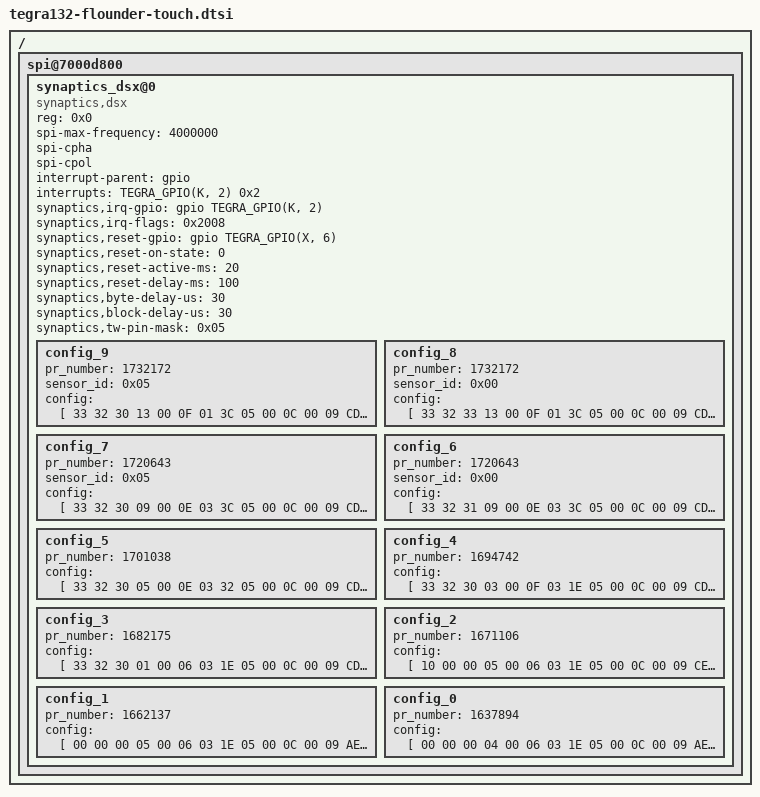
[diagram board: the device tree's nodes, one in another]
/ {
	spi@7000d800 {
		synaptics_dsx@0 {
			compatible = "synaptics,dsx";
			reg = <0x0>;
			spi-max-frequency = <4000000>;
			spi-cpha;
			spi-cpol;
			interrupt-parent = <&gpio>;
			interrupts = <TEGRA_GPIO(K, 2) 0x2>;
			synaptics,irq-gpio = <&gpio TEGRA_GPIO(K, 2) 0x00>;
			synaptics,irq-flags = <0x2008>;
			synaptics,reset-gpio = <&gpio TEGRA_GPIO(X, 6) 0x00>;
			synaptics,reset-on-state = <0>;
			synaptics,reset-active-ms = <20>;
			synaptics,reset-delay-ms = <100>;
			synaptics,byte-delay-us = <30>;
			synaptics,block-delay-us = <30>;
			synaptics,tw-pin-mask = <0x05>;

			config_9 {
				pr_number     = <1732172>;
				sensor_id     = <0x05>;
				config = [
					33 32 30 13 00 0F 01 3C
					05 00 0C 00 09 CD 4C CD
					4C 0D 0D 00 00 26 1C 1E
					05 92 14 58 07 32 36 FF
					38 FE F0 D2 F0 D2 C3 80
					C4 C4 05 03 1C 23 00 0F
					0A 20 01 01 05 00 00 0A
					C0 19 32 26 26 80 80 00
					00 C8 2F 14 00 10 B4 00
					14 00 00 00 00 00 00 FC
					E6 00 00 0A 32 50 99 40
					00 50 00 00 55 00 80 00
					01 64 00 FF FF 5A 5A 01
					40 40 32 04 00 00 00 00
					00 0C 00 09 50 64 00 00
					00 00 4C 04 6C 07 1E 05
					00 00 00 01 05 0A 00 01
					14 03 06 0F 0A FF 00 C8
					00 80 04 1B 00 00 00 E8
					03 FF FF BF F5 FF FF 00
					C0 80 00 71 00 E8 03 01
					00 03 03 07 07 00 E8 03
					02 04 01 04 83 2C 00 14
					00 00 00 02 00 02 56 03
					2B 00 13 00 01 00 02 00
					02 5A 03 2A 00 13 00 02
					00 02 00 02 5C 03 29 00
					12 00 03 00 02 00 02 5E
					83 28 00 12 00 02 02 02
					00 02 60 83 28 00 12 00
					05 00 02 00 02 62 83 27
					00 11 00 02 04 02 00 02
					64 82 25 00 11 00 06 02
					02 00 02 68 05 05 05 05
					05 05 05 04 04 04 04 04
					04 04 04 04 04 04 04 04
					04 04 04 04 04 04 04 04
					04 04 04 04 05 05 05 05
					05 05 0B 0B 0B 0B 0B 0B
					0B 0B 0B 07 07 07 07 07
					07 07 07 07 07 07 07 07
					07 07 07 07 07 07 07 07
					07 07 07 07 07 07 07 07
					0F 0F 07 07 07 07 07 05
					05 05 03 03 03 02 02 02
					01 01 01 01 01 01 01 01
					01 03 05 0F 1B 1B 01 00
					07 1B 1B 05 01 07 1E 00
					05 00 A6 00 14 64 01 00
					00 03 03 00 00 07 07 00
					32 05 06 00 35 35 00 05
					00 00 07 07 06 06 00 00
					03 05 32 C8 0C 26 0A 01
					05 08 08 A0 00 A0 00 64
					64 80 FE 00 00 00 00 00
					00 63 00 05 00 00 00 00
					0B 00 00 00 00 00 B2 03
					14 00 06 AB 03 14 00 06
					00 15 5B 50 5A 32 1E 00
					12 00 90 C6 00 3E 41 47
					49 37 3F 35 33 30 36 24
					4A 1F 1E 22 1A 1B 16 18
					34 32 31 2F 2B 28 2C 2A
					25 2D 23 20 21 1D 1C 17
					19 14 13 0F 0A 10 0C 0B
					05 03 08 06 0E 09 07 52
					56 5C 5E 54 55 53 58 57
					59 5B 5D 60 5F 63 62 02
					10 02 10 02 10 02 10 00
					10 00 10 00 10 00 10 F0
					0A 0A 0A 0A 1E
				];
			};

			config_8 {
				pr_number     = <1732172>;
				sensor_id     = <0x00>;
				config = [
					33 32 33 13 00 0F 01 3C
					05 00 0C 00 09 CD 4C CD
					4C 0D 0D 00 00 26 1C 1E
					05 86 16 CD 07 32 33 FF
					2E 00 F0 D2 F0 D2 C3 80
					C4 C4 05 03 1C 23 00 0F
					0A 20 01 01 05 00 00 0A
					C0 19 32 26 26 80 80 00
					00 C8 2F 14 00 10 B4 00
					14 00 00 00 00 00 00 FC
					E6 00 00 0A 32 50 99 40
					00 50 00 00 55 00 80 00
					01 64 00 FF FF 5A 5A 01
					40 40 32 04 00 00 00 00
					00 0C 00 09 50 64 00 00
					00 00 4C 04 6C 07 1E 05
					00 00 00 01 05 0A 00 01
					14 03 06 0F 0A FF 04 C8
					00 80 04 1B 00 00 00 E8
					03 FF FF BF F5 FF FF 00
					C0 80 00 71 00 E8 03 01
					00 03 03 07 07 00 E8 03
					02 04 01 04 85 3F 00 14
					00 00 00 02 00 02 56 04
					3D 00 13 00 01 00 02 00
					02 5A 04 3C 00 13 00 02
					00 02 00 02 5C 04 3B 00
					12 00 03 00 02 00 02 5E
					84 39 00 12 00 03 01 02
					00 02 60 84 38 00 12 00
					05 00 02 00 02 62 84 37
					00 11 00 03 03 02 00 02
					64 84 35 00 11 00 02 06
					02 00 02 68 05 05 05 05
					05 05 05 04 04 04 04 04
					04 04 04 04 04 04 04 04
					04 04 04 04 04 04 04 04
					04 04 04 04 05 05 05 05
					05 05 0B 0B 0B 0B 0B 0B
					0B 0B 0B 07 07 07 07 07
					07 07 07 07 07 07 07 07
					07 07 07 07 07 07 07 07
					07 07 07 07 07 07 07 07
					0F 0F 0F 0B 0C 09 07 05
					05 05 03 03 03 01 00 00
					00 00 01 00 01 01 02 02
					04 03 05 0F 1B 1B 01 00
					07 1B 1B 05 01 07 1E 00
					05 00 A6 00 14 64 03 00
					00 03 03 00 00 07 07 00
					2F 05 06 00 35 35 00 05
					00 00 07 07 06 06 00 00
					03 05 32 C8 0C 26 0A 01
					00 05 05 A0 00 A0 00 64
					64 80 FE 00 00 00 00 00
					00 63 00 05 00 00 00 00
					0B 00 00 00 00 00 B2 03
					14 00 06 9B 03 14 00 06
					00 15 5A 50 5A 32 1E 00
					79 00 10 C0 00 3E 41 47
					49 37 3F 35 33 30 36 24
					4A 1F 1E 22 1A 1B 16 18
					34 32 31 2F 2B 28 2C 2A
					25 2D 23 20 21 1D 1C 17
					19 14 13 0F 0A 10 0C 0B
					05 03 08 06 0E 09 07 52
					56 5C 5E 54 55 53 58 57
					59 5B 5D 60 5F 63 62 02
					10 02 10 02 10 02 10 00
					10 00 10 00 10 00 10 F0
					0A 0A 0A 0A 1E
				];
			};

			config_7 {
				pr_number     = <1720643>;
				sensor_id     = <0x05>;
				config = [
					33 32 30 09 00 0E 03 3C
					05 00 0C 00 09 CD 4C CD
					4C 0D 0D 00 00 26 1C 1E
					05 92 14 58 07 32 36 FF
					38 FE F0 D2 F0 D2 C3 80
					C4 C4 05 03 1C 23 00 0F
					0A 20 01 01 05 00 00 0A
					C0 19 32 26 26 80 80 00
					00 C8 2F 14 00 10 B4 00
					14 00 00 00 00 00 00 FC
					E6 00 00 0A 32 50 99 40
					00 50 00 00 55 00 80 00
					01 64 00 FF FF 5A 5A 01
					40 40 32 04 00 00 00 00
					00 0C 00 09 50 64 00 00
					00 00 4C 04 6C 07 1E 05
					00 00 00 01 05 0A 00 01
					14 03 06 0F 0A FF 04 C8
					00 80 04 1B 00 00 00 E8
					03 FF FF BF F5 FF FF 00
					C0 80 00 71 00 E8 03 01
					00 03 03 07 07 00 E8 03
					02 05 01 04 83 28 00 14
					00 00 00 02 00 02 56 03
					28 00 13 00 01 00 02 00
					02 5A 03 28 00 13 00 02
					00 02 00 02 5C 03 28 00
					12 00 03 00 02 00 02 5E
					83 28 00 12 00 04 00 02
					00 02 60 03 28 00 12 00
					05 00 02 00 02 62 83 28
					00 11 00 06 00 02 00 02
					64 83 28 00 11 00 07 00
					02 00 02 66 05 05 05 05
					05 05 05 04 04 04 04 04
					04 04 04 04 04 04 04 04
					04 04 04 04 04 04 04 04
					04 04 04 04 05 05 05 05
					05 05 0B 0B 0B 0B 0B 0B
					0B 0B 0B 07 07 07 07 07
					07 07 07 07 07 07 07 07
					07 07 07 07 07 07 07 07
					07 07 07 07 07 07 07 07
					0F 0F 07 07 07 07 07 05
					05 05 03 03 03 02 02 02
					01 01 01 01 01 01 01 01
					01 03 05 0F 1B 1B 01 00
					07 1B 1B 05 01 07 1E 00
					05 00 A6 00 14 64 01 00
					00 03 03 00 00 07 07 00
					32 05 06 00 35 35 00 05
					00 00 07 07 06 06 00 00
					03 05 32 C8 0C 26 0A 01
					05 08 08 A0 00 A0 00 64
					64 80 FE 00 00 00 00 00
					00 63 00 05 00 00 00 00
					0B 00 00 00 00 00 B2 03
					14 00 06 AB 03 14 00 06
					00 15 5B 50 5A 32 1E 00
					0A 00 90 C0 00 3E 41 47
					49 37 3F 35 33 30 36 24
					4A 1F 1E 22 1A 1B 16 18
					34 32 31 2F 2B 28 2C 2A
					25 2D 23 20 21 1D 1C 17
					19 14 13 0F 0A 10 0C 0B
					05 03 08 06 0E 09 07 52
					56 5C 5E 54 55 53 58 57
					59 5B 5D 60 5F 63 62 02
					10 02 10 02 10 02 10 00
					10 00 10 00 10 00 10 F0
					0A 0A 0A 0A 1E
				];
			};

			config_6 {
				pr_number     = <1720643>;
				sensor_id     = <0x00>;
				config = [
					33 32 31 09 00 0E 03 3C
					05 00 0C 00 09 CD 4C CD
					4C 0D 0D 00 00 26 1C 1E
					05 86 16 CD 07 32 33 FF
					2E 00 F0 D2 F0 D2 C3 80
					C4 C4 05 03 1C 23 00 0F
					0A 20 01 01 05 00 00 0A
					C0 19 32 26 26 80 80 00
					00 C8 2F 14 00 10 B4 00
					14 00 01 00 00 00 00 FC
					E6 00 00 0A 32 50 99 40
					00 50 00 00 55 00 80 00
					01 64 00 FF FF 5A 5A 01
					40 40 32 04 00 00 00 00
					00 0C 00 09 50 64 00 00
					00 00 4C 04 6C 07 1E 05
					00 00 00 01 05 0A 00 01
					14 03 06 0F 0A FF 04 C8
					00 80 04 1B 00 00 00 E8
					03 FF FF BF F5 FF FF 00
					C0 80 00 71 00 E8 03 01
					00 03 03 07 07 00 E8 03
					02 05 01 04 83 29 00 14
					00 00 00 02 00 02 56 03
					28 00 13 00 01 00 02 00
					02 5A 03 27 00 13 00 01
					01 02 00 02 5C 02 26 00
					12 00 02 01 02 00 02 5E
					82 25 00 12 00 03 01 02
					00 02 60 82 24 00 12 00
					03 02 02 00 02 62 82 23
					00 11 00 04 02 02 00 02
					64 82 22 00 11 00 05 03
					02 00 02 68 05 05 05 05
					05 05 05 04 04 04 04 04
					04 04 04 04 04 04 04 04
					04 04 04 04 04 04 04 04
					04 04 04 04 05 05 05 05
					05 05 0B 0B 0B 0B 0B 0B
					0B 0B 0B 07 07 07 07 07
					07 07 07 07 07 07 07 07
					07 07 07 07 07 07 07 07
					07 07 07 07 07 07 07 07
					0F 0F 08 08 08 07 07 05
					05 05 03 03 03 01 02 02
					00 00 01 01 01 01 01 01
					01 03 05 0F 1B 1B 01 00
					07 1B 1B 05 01 07 1E 00
					05 00 A6 00 14 64 01 00
					00 03 03 00 00 07 07 00
					32 05 06 00 35 35 00 05
					00 00 07 07 06 06 00 00
					03 05 32 C8 0C 26 0A 01
					05 08 08 A0 00 A0 00 64
					64 80 FE 00 00 00 00 00
					00 63 00 05 00 00 00 00
					0B 00 00 00 00 00 B2 03
					14 00 06 9B 03 14 00 06
					00 15 5B 50 5A 32 1E 00
					0A 00 90 C0 00 3E 41 47
					49 37 3F 35 33 30 36 24
					4A 1F 1E 22 1A 1B 16 18
					34 32 31 2F 2B 28 2C 2A
					25 2D 23 20 21 1D 1C 17
					19 14 13 0F 0A 10 0C 0B
					05 03 08 06 0E 09 07 52
					56 5C 5E 54 55 53 58 57
					59 5B 5D 60 5F 63 62 02
					10 02 10 02 10 02 10 00
					10 00 10 00 10 00 10 F0
					0A 0A 0A 0A 1E
				];
			};

			config_5 {				/* JDI */
				pr_number     = <1701038>;
				config = [
					33 32 30 05 00 0E 03 32
					05 00 0C 00 09 CD 4C CD
					4C 0D 0D 00 00 26 1C 1E
					05 AA 15 1E 05 2D 30 FD
					43 FA F0 D2 F0 D2 C3 80
					C4 C4 05 03 1E 28 00 0F
					0A 20 01 01 05 00 00 0A
					C0 19 32 26 26 80 80 00
					00 C8 2F 14 00 10 B4 00
					14 00 01 00 00 00 00 FC
					E6 00 00 0A 32 50 99 40
					00 50 00 00 55 00 80 00
					01 64 00 FF FF 80 80 01
					40 40 32 04 00 00 00 00
					00 0C 00 09 50 64 00 00
					00 00 4C 04 6C 07 1E 05
					00 00 00 01 05 0A 00 01
					14 03 06 0F 0A FF 00 C8
					00 80 04 1B 00 00 00 E8
					03 FF FF BF 32 FF FF 00
					C0 80 00 71 00 E8 03 01
					00 03 03 07 07 00 E8 03
					02 05 01 04 83 30 00 14
					00 00 00 02 00 02 56 03
					2F 00 13 00 01 00 02 00
					02 5A 83 2E 00 13 00 02
					00 02 00 02 5C 03 2D 00
					12 00 03 00 02 00 02 5E
					03 2C 00 12 00 04 00 02
					00 02 60 03 2B 00 12 00
					05 00 02 00 02 62 83 2A
					00 11 00 06 00 02 00 02
					64 83 28 00 11 00 08 00
					02 00 02 68 05 05 05 05
					05 05 05 04 04 04 04 04
					04 04 04 04 04 04 04 04
					04 04 04 04 04 04 04 04
					04 04 04 04 05 05 05 05
					05 05 0B 0B 0B 0B 0B 0B
					0B 0B 0B 07 07 07 07 07
					07 07 07 07 07 07 07 07
					07 07 07 07 07 07 07 07
					07 07 07 07 07 07 07 07
					0F 0F 07 07 07 07 07 05
					05 05 03 03 03 02 02 02
					01 01 01 01 01 01 01 01
					01 03 05 0F 1B 1B 01 00
					07 1B 1B 05 01 07 1E 00
					05 00 A6 00 14 64 01 00
					00 03 03 00 00 07 07 00
					32 05 06 00 1E 1E 00 05
					00 00 07 07 06 06 00 00
					03 05 32 C8 0C 26 0A 01
					05 0C 0C A0 00 A0 00 50
					50 80 FE 00 00 00 00 00
					00 63 00 05 00 00 00 00
					0B 00 00 00 00 00 B2 03
					14 00 06 BB 03 14 00 06
					00 15 5A 50 5A 32 1E 00
					00 00 10 C0 00 3E 41 47
					49 37 3F 35 33 30 36 24
					4A 1F 1E 22 1A 1B 16 18
					34 32 31 2F 2B 28 2C 2A
					25 2D 23 20 21 1D 1C 17
					19 14 13 0F 0A 10 0C 0B
					05 03 08 06 0E 09 07 52
					56 5C 5E 54 55 53 58 57
					59 5B 5D 60 5F 63 62 02
					10 02 10 02 10 02 10 00
					10 00 10 00 10 00 10 F0
					0A 0A 0A 0A 1E
				];
			};

			config_4 {
				pr_number     = <1694742>;
				config = [
					33 32 30 03 00 0F 03 1E
					05 00 0C 00 09 CD 4C CD
					4C 0D 0D 00 00 26 1C 1E
					05 AA 15 1E 05 2D 30 FD
					43 FA F0 D2 F0 D2 C3 80
					C4 C4 05 03 1E 28 00 0F
					0A 20 01 01 05 00 00 0A
					C0 19 32 26 26 80 80 00
					00 C8 2F 14 00 10 00 00
					00 00 01 00 00 00 00 FC
					E6 00 00 0A 32 50 99 40
					00 50 00 00 55 00 80 00
					01 64 00 FF FF 80 80 01
					40 40 32 04 00 00 00 00
					00 0C 00 09 50 64 00 00
					00 00 4C 04 6C 07 1E 05
					00 00 00 01 05 0A 00 01
					14 03 06 0F 0A FF 04 C8
					00 80 04 1B 00 00 00 E8
					03 FF FF BF F5 FF FF 00
					C0 80 00 71 00 E8 03 01
					00 03 03 07 07 00 E8 03
					02 05 01 04 83 28 00 14
					00 00 00 02 00 02 56 03
					28 00 13 00 01 00 02 00
					02 5A 03 28 00 13 00 02
					00 02 00 02 5C 03 28 00
					12 00 03 00 02 00 02 5E
					83 28 00 12 00 04 00 02
					00 02 60 03 28 00 12 00
					05 00 02 00 02 62 83 28
					00 11 00 06 00 02 00 02
					64 83 28 00 11 00 07 00
					02 00 02 66 05 05 05 05
					05 05 05 04 04 04 04 04
					04 04 04 04 04 04 04 04
					04 04 04 04 04 04 04 04
					04 04 04 04 05 05 05 05
					05 05 0B 0B 0B 0B 0B 0B
					0B 0B 0B 07 07 07 07 07
					07 07 07 07 07 07 07 07
					07 07 07 07 07 07 07 07
					07 07 07 07 07 07 07 07
					0F 0F 07 07 07 07 07 05
					05 05 03 03 03 02 02 02
					01 01 01 01 01 01 01 01
					01 03 05 0F 1B 1B 01 00
					07 1B 1B 05 01 07 1E 00
					05 00 A6 00 14 64 01 00
					00 03 03 00 00 07 07 00
					32 05 06 00 1E 1E 00 05
					00 00 07 07 06 06 00 00
					03 05 32 C8 0C 26 0A 01
					05 08 08 A0 00 A0 00 50
					50 80 FE 00 00 00 00 00
					00 63 00 05 00 00 00 00
					0B 00 00 00 00 00 B2 03
					14 00 06 BB 03 14 00 06
					00 15 5B 50 5A 32 1E 00
					0A 00 90 C0 00 3E 41 47
					49 37 3F 35 33 30 36 24
					4A 1F 1E 22 1A 1B 16 18
					34 32 31 2F 2B 28 2C 2A
					25 2D 23 20 21 1D 1C 17
					19 14 13 0F 0A 10 0C 0B
					05 03 08 06 0E 09 07 52
					56 5C 5E 54 55 53 58 57
					59 5B 5D 60 5F 63 62 02
					10 02 10 02 10 02 10 00
					10 00 10 00 10 00 10 F0
					0A 0A 0A 0A 1E 14
				];
			};

			config_3 {
				pr_number     = <1682175>;
				config = [
					33 32 30 01 00 06 03 1E
					05 00 0C 00 09 CD 4C CD
					4C 0D 0D 00 00 26 1C 1E
					05 AA 15 1E 05 2D 30 FD
					43 FA F0 D2 F0 D2 C3 80
					C4 C4 05 03 1E 28 00 0F
					0A 20 01 01 05 00 00 0A
					C0 19 32 26 26 80 80 00
					00 C8 2F 14 00 10 00 00
					00 00 01 00 00 00 00 FC
					E6 00 00 0A 32 50 99 40
					00 50 00 00 55 00 80 00
					01 64 00 FF FF 80 80 01
					40 40 32 04 00 00 00 00
					00 0C 00 09 3C 32 00 00
					00 00 4C 04 6C 07 1E 05
					00 00 00 01 05 0A 00 01
					14 03 06 0F 0A FF 00 C8
					00 80 04 1B 00 00 00 E8
					03 FF FF BF F5 FF FF 00
					C0 80 00 71 00 E8 03 01
					00 03 03 07 07 00 E8 03
					02 05 01 04 83 28 00 14
					00 00 00 02 00 02 56 03
					28 00 13 00 01 00 02 00
					02 5A 03 28 00 13 00 02
					00 02 00 02 5C 03 28 00
					12 00 03 00 02 00 02 5E
					03 28 00 12 00 04 00 02
					00 02 60 03 28 00 12 00
					05 00 02 00 02 62 03 28
					00 11 00 06 00 02 00 02
					64 03 28 00 11 00 07 00
					02 00 02 66 05 05 05 05
					05 05 05 04 04 04 04 04
					04 04 04 04 04 04 04 04
					04 04 04 04 04 04 04 04
					04 04 04 04 05 05 05 05
					05 05 0B 0B 0B 0B 0B 0B
					0B 0B 0B 07 07 07 07 07
					07 07 07 07 07 07 07 07
					07 07 07 07 07 07 07 07
					07 07 07 07 07 07 07 07
					0F 0F 07 07 07 07 07 05
					05 05 03 03 03 02 02 02
					01 01 01 01 01 01 01 01
					01 03 05 0F 1B 1B 01 00
					07 1B 1B 05 01 07 1E 00
					05 00 A6 00 14 64 01 00
					00 03 03 00 00 07 07 00
					32 05 06 00 1E 1E 00 05
					00 00 07 07 06 06 00 00
					03 05 32 C8 0C 26 0A 01
					05 08 08 A0 00 A0 00 50
					50 80 FE 00 00 00 00 00
					00 63 00 05 00 00 00 00
					0B 00 00 00 00 00 B2 03
					14 00 06 BB 03 14 00 06
					00 15 5A 50 5A 32 1E 00
					00 00 10 C0 00 3E 41 47
					49 37 3F 35 33 30 36 24
					4A 1F 1E 22 1A 1B 16 18
					34 32 31 2F 2B 28 2C 2A
					25 2D 23 20 21 1D 1C 17
					19 14 13 0F 0A 10 0C 0B
					05 03 08 06 0E 09 07 52
					56 5C 5E 54 55 53 58 57
					59 5B 5D 60 5F 63 62 02
					10 02 10 02 10 02 10 00
					10 00 10 00 10 00 10 F0
					0A 0A 0A 0A 1E 0A
				];
			};

			config_2 {
				pr_number     = <1671106>;
				config = [
					10 00 00 05 00 06 03 1E
					05 00 0C 00 09 CE 3E 72
					45 10 10 0F 0F 26 1C 1E
					05 AA 15 1E 05 2D 30 FD
					43 FA F0 D2 F0 D2 C3 80
					C4 C4 05 03 1E 28 00 0F
					0A 01 01 05 00 00 0A C0
					19 32 26 26 80 80 00 00
					2F 14 00 10 00 00 00 00
					01 00 00 00 00 FC E6 00
					00 0A 32 50 99 40 00 50
					00 00 55 00 80 00 01 64
					00 FF FF 80 80 01 40 40
					32 04 00 00 00 00 00 0C
					00 09 3C 32 00 00 00 00
					4C 04 6C 07 1E 05 00 00
					00 01 05 0A 00 01 FF 00
					2A 01 80 04 1B 00 00 00
					E8 03 FF FF BF F5 FF FF
					00 C0 80 00 71 00 E8 03
					01 00 03 03 07 07 03 E8
					03 02 05 01 04 83 28 00
					14 00 00 00 02 00 02 56
					03 28 00 13 00 01 00 02
					00 02 5A 03 28 00 13 00
					02 00 02 00 02 5C 03 28
					00 12 00 03 00 02 00 02
					5E 03 28 00 12 00 04 00
					02 00 02 60 03 28 00 12
					00 05 00 02 00 02 62 03
					28 00 11 00 06 00 02 00
					02 64 03 28 00 11 00 07
					00 02 00 02 66 05 05 05
					05 05 05 05 04 04 04 04
					04 04 04 04 04 04 04 04
					04 04 04 04 04 04 04 04
					04 04 04 04 04 05 05 05
					05 05 05 0B 0B 0B 0B 0B
					0B 0B 0B 0B 07 07 07 07
					07 07 07 07 07 07 07 07
					07 07 07 07 07 07 07 07
					07 07 07 07 07 07 07 07
					07 0F 0F 07 07 07 07 07
					05 05 05 03 03 03 02 02
					02 01 01 01 01 01 01 01
					01 01 03 05 0F 1B 1B 01
					00 07 1B 1B 05 01 07 1E
					00 05 00 A6 00 14 64 01
					00 00 03 03 00 00 07 07
					00 32 05 06 00 1E 1E 00
					05 00 00 07 07 06 06 00
					00 03 05 32 C8 0C 26 0A
					80 FE 00 00 00 00 00 00
					63 00 05 00 00 00 00 0B
					00 00 00 00 00 B2 03 14
					00 06 BB 03 14 00 06 00
					15 5A 50 5A 32 1E 00 00
					00 00 00 00 3E 41 47 49
					37 3F 35 33 30 36 24 4A
					1F 1E 22 1A 1B 16 18 34
					32 31 2F 2B 28 2C 2A 25
					2D 23 20 21 1D 1C 17 19
					14 13 0F 0A 10 0C 0B 05
					03 08 06 0E 09 07 52 56
					5C 5E 54 55 53 58 57 59
					5B 5D 60 5F 63 62 02 10
					02 10 02 10 02 10 00 10
					00 10 00 10 00 10 FF 0A
					0A 0A 0A 1E 0A
				];
			};

			config_1 {
				pr_number     = <1662137>;
				config = [
					00 00 00 05 00 06 03 1E
					05 00 0C 00 09 AE 4B 9A
					4D 0E 0E 0D 0D 26 1C 1E
					05 58 10 A0 03 2D 1D 01
					32 00 52 BA 36 BE C3 80
					C4 C4 05 03 1E 28 00 0F
					0A 01 01 07 05 05 0A C0
					19 C8 26 26 80 80 00 00
					2F 14 00 10 00 00 00 00
					00 00 00 00 00 FC E6 00
					00 0A 32 50 99 40 00 50
					00 00 55 00 80 00 01 64
					00 FF FF 66 66 01 40 40
					32 3C 00 00 00 00 00 0C
					00 09 3C 32 00 00 00 00
					4C 04 6C 07 1E 05 00 00
					00 01 05 0A 00 01 FF 00
					17 01 80 04 1B 00 00 00
					C8 00 FF FF BF 64 88 13
					00 C0 80 00 71 00 D0 07
					0A 00 03 03 07 07 03 D0
					07 01 04 04 3B 00 13 00
					00 00 02 00 02 5A 84 3A
					00 12 00 01 00 02 00 02
					5E 04 39 00 12 00 02 00
					02 00 02 60 84 38 00 12
					00 03 00 02 00 02 62 84
					36 00 11 00 04 00 02 00
					02 64 84 34 00 11 00 06
					00 02 00 02 68 03 32 00
					10 00 08 00 02 00 02 6C
					83 30 00 10 00 0A 00 05
					00 04 5A 05 05 05 05 05
					05 05 05 05 05 05 05 05
					05 05 05 04 05 05 04 04
					05 05 05 05 04 05 05 05
					05 05 05 05 05 05 05 05
					05 20 00 05 00 A6 00 14
					64 01 00 07 07 06 06 00
					00 03 05 32 C8 0C 26 0A
					80 FE 00 00 00 00 00 00
					63 00 05 00 00 00 00 0B
					00 00 00 00 00 00 00 3E
					41 47 49 37 3F 35 33 30
					36 24 4A 1F 1E 22 1A 1B
					16 18 34 32 31 2F 2B 28
					2C 2A 25 2D 23 20 21 1D
					1C 17 19 14 13 0F 0A 10
					0C 0B 05 03 08 06 0E 09
					07 52 56 5C 5E 54 55 53
					58 57 59 5B 5D 60 5F 63
					62 02 10 02 10 02 10 02
					10 00 10 00 10 00 10 00
					10 FF 0A 0A 0A 0A 01
				];
			};

			config_0 {
				pr_number     = <1637894>;
				config = [
					00 00 00 04 00 06 03 1E
					05 00 0C 00 09 AE 4B 9A
					4D 0E 0E 0D 0D 26 1C 1E
					05 58 10 A0 03 2D 1D 01
					32 00 52 BA 36 BE C3 80
					C4 C4 05 03 0F 28 50 0F
					0A 01 01 07 05 05 0A C0
					19 C8 26 26 80 80 00 00
					2F 14 00 10 00 00 00 00
					00 00 00 00 00 FC E6 00
					00 0A 32 50 99 40 00 50
					00 00 55 00 80 00 01 64
					00 FF FF 80 80 01 40 40
					32 3C 00 00 00 00 00 0C
					00 09 3C 32 00 00 00 00
					4C 04 6C 07 1E 05 00 00
					00 01 05 0A 00 01 FF 00
					04 01 80 04 1B 00 00 00
					C8 00 FF FF BF 64 F4 01
					00 C0 80 00 71 00 E8 03
					14 00 03 03 07 07 03 E8
					03 01 04 03 32 00 10 00
					00 00 02 00 02 6A 03 30
					00 10 00 02 00 05 00 04
					5A 03 2F 00 0F 00 04 00
					05 00 04 5D 03 2D 00 0F
					00 06 00 04 00 03 5A 03
					2C 00 0E 00 08 00 04 00
					03 5D 03 2A 00 0E 00 0A
					00 04 00 03 60 03 29 00
					0D 00 0C 00 03 00 02 58
					03 28 00 0D 00 0E 00 03
					00 02 5B 05 05 05 05 05
					05 05 05 05 05 05 05 05
					05 05 05 05 05 05 05 05
					05 05 05 05 05 05 05 05
					05 05 05 05 05 05 05 05
					05 28 00 05 00 A6 00 14
					64 05 00 07 07 06 06 00
					00 03 05 32 C8 0C 26 0A
					80 FE 00 00 00 00 00 00
					63 00 05 00 00 00 00 0B
					00 00 00 00 00 00 00 3E
					41 47 49 37 3F 35 33 30
					36 24 4A 1F 1E 22 1A 1B
					16 18 34 32 31 2F 2B 28
					2C 2A 25 2D 23 20 21 1D
					1C 17 19 14 13 0F 0A 10
					0C 0B 05 03 08 06 0E 09
					07 52 56 5C 5E 54 55 53
					58 57 59 5B 5D 60 5F 63
					62 02 10 02 10 02 10 02
					10 00 10 00 10 00 10 00
					10 9B 0A 0A 0A 0A 01
				];
			};
		};
	};
};
